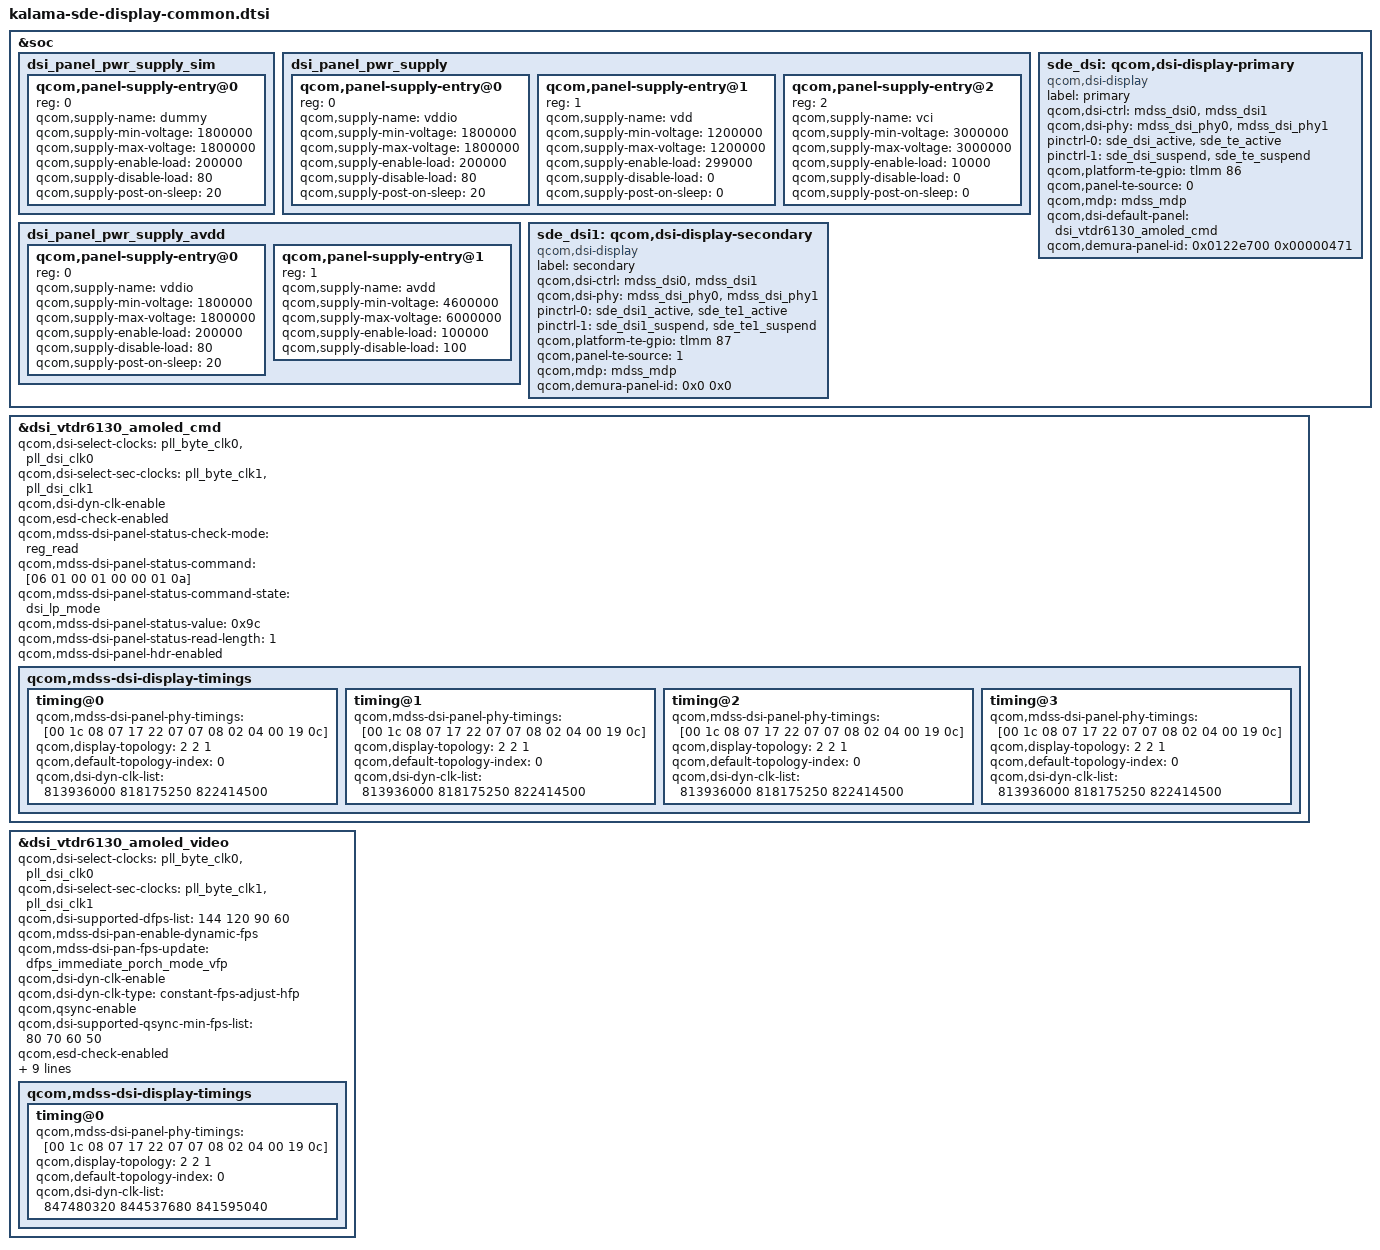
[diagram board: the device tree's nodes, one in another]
#include "dsi-panel-vtdr6130-dsc-fhd-plus-cmd.dtsi"
#include "dsi-panel-vtdr6130-dsc-fhd-plus-video.dtsi"

#include "kalama-sde-display-pinctrl.dtsi"

&soc {
	dsi_panel_pwr_supply_sim: dsi_panel_pwr_supply_sim {
		#address-cells = <1>;
		#size-cells = <0>;

		qcom,panel-supply-entry@0 {
			reg = <0>;
			qcom,supply-name = "dummy";
			qcom,supply-min-voltage = <1800000>;
			qcom,supply-max-voltage = <1800000>;
			qcom,supply-enable-load = <200000>;
			qcom,supply-disable-load = <80>;
			qcom,supply-post-on-sleep = <20>;
		};
	};

	dsi_panel_pwr_supply: dsi_panel_pwr_supply {
		#address-cells = <1>;
		#size-cells = <0>;

		qcom,panel-supply-entry@0 {
			reg = <0>;
			qcom,supply-name = "vddio";
			qcom,supply-min-voltage = <1800000>;
			qcom,supply-max-voltage = <1800000>;
			qcom,supply-enable-load = <200000>;
			qcom,supply-disable-load = <80>;
			qcom,supply-post-on-sleep = <20>;
		};

		qcom,panel-supply-entry@1 {
			reg = <1>;
			qcom,supply-name = "vdd";
			qcom,supply-min-voltage = <1200000>;
			qcom,supply-max-voltage = <1200000>;
			qcom,supply-enable-load = <299000>;
			qcom,supply-disable-load = <0>;
			qcom,supply-post-on-sleep = <0>;
		};

		qcom,panel-supply-entry@2 {
			reg = <2>;
			qcom,supply-name = "vci";
			qcom,supply-min-voltage = <3000000>;
			qcom,supply-max-voltage = <3000000>;
			qcom,supply-enable-load = <10000>;
			qcom,supply-disable-load = <0>;
			qcom,supply-post-on-sleep = <0>;
		};
	};

	dsi_panel_pwr_supply_avdd: dsi_panel_pwr_supply_avdd {
		#address-cells = <1>;
		#size-cells = <0>;

		qcom,panel-supply-entry@0 {
			reg = <0>;
			qcom,supply-name = "vddio";
			qcom,supply-min-voltage = <1800000>;
			qcom,supply-max-voltage = <1800000>;
			qcom,supply-enable-load = <200000>;
			qcom,supply-disable-load = <80>;
			qcom,supply-post-on-sleep = <20>;
		};

		qcom,panel-supply-entry@1 {
			reg = <1>;
			qcom,supply-name = "avdd";
			qcom,supply-min-voltage = <4600000>;
			qcom,supply-max-voltage = <6000000>;
			qcom,supply-enable-load = <100000>;
			qcom,supply-disable-load = <100>;
		};
	};

	sde_dsi: qcom,dsi-display-primary {
		compatible = "qcom,dsi-display";
		label = "primary";

		qcom,dsi-ctrl = <&mdss_dsi0 &mdss_dsi1>;
		qcom,dsi-phy = <&mdss_dsi_phy0 &mdss_dsi_phy1>;

		pinctrl-names = "panel_active", "panel_suspend";
		pinctrl-0 = <&sde_dsi_active &sde_te_active>;
		pinctrl-1 = <&sde_dsi_suspend &sde_te_suspend>;

		qcom,platform-te-gpio = <&tlmm 86 0>;
		qcom,panel-te-source = <0>;

		qcom,mdp = <&mdss_mdp>;
		qcom,dsi-default-panel = <&dsi_vtdr6130_amoled_cmd>;
		qcom,demura-panel-id = <0x0122e700 0x00000471>;
	};

	sde_dsi1: qcom,dsi-display-secondary {
		compatible = "qcom,dsi-display";
		label = "secondary";

		qcom,dsi-ctrl = <&mdss_dsi0 &mdss_dsi1>;
		qcom,dsi-phy = <&mdss_dsi_phy0 &mdss_dsi_phy1>;

		pinctrl-names = "panel_active", "panel_suspend";
		pinctrl-0 = <&sde_dsi1_active &sde_te1_active>;
		pinctrl-1 = <&sde_dsi1_suspend &sde_te1_suspend>;

		qcom,platform-te-gpio = <&tlmm 87 0>;
		qcom,panel-te-source = <1>;

		qcom,mdp = <&mdss_mdp>;
		qcom,demura-panel-id = <0x0 0x0>;
	};
};

/* PHY TIMINGS REVISION YL with reduced margins */
&dsi_vtdr6130_amoled_cmd {
	qcom,dsi-select-clocks = "pll_byte_clk0", "pll_dsi_clk0";
	qcom,dsi-select-sec-clocks = "pll_byte_clk1", "pll_dsi_clk1";

	qcom,dsi-dyn-clk-enable;

	qcom,esd-check-enabled;
	qcom,mdss-dsi-panel-status-check-mode = "reg_read";
	qcom,mdss-dsi-panel-status-command = [06 01 00 01 00 00 01 0a];
	qcom,mdss-dsi-panel-status-command-state = "dsi_lp_mode";
	qcom,mdss-dsi-panel-status-value = <0x9c>;
	qcom,mdss-dsi-panel-status-read-length = <1>;

	qcom,mdss-dsi-panel-hdr-enabled;

	qcom,mdss-dsi-display-timings {
		timing@0 {
			qcom,mdss-dsi-panel-phy-timings = [00 1c 08 07 17 22 07
				07 08 02 04 00 19 0c];
			qcom,display-topology = <2 2 1>;
			qcom,default-topology-index = <0>;
			qcom,dsi-dyn-clk-list = <813936000 818175250 822414500>;
		};
		timing@1 {
			qcom,mdss-dsi-panel-phy-timings = [00 1c 08 07 17 22 07
				07 08 02 04 00 19 0c];
			qcom,display-topology = <2 2 1>;
			qcom,default-topology-index = <0>;
			qcom,dsi-dyn-clk-list = <813936000 818175250 822414500>;
		};
		timing@2 {
			qcom,mdss-dsi-panel-phy-timings = [00 1c 08 07 17 22 07
				07 08 02 04 00 19 0c];
			qcom,display-topology = <2 2 1>;
			qcom,default-topology-index = <0>;
			qcom,dsi-dyn-clk-list = <813936000 818175250 822414500>;
		};
		timing@3 {
			qcom,mdss-dsi-panel-phy-timings = [00 1c 08 07 17 22 07
				07 08 02 04 00 19 0c];
			qcom,display-topology = <2 2 1>;
			qcom,default-topology-index = <0>;
			qcom,dsi-dyn-clk-list = <813936000 818175250 822414500>;
		};
	};
};

&dsi_vtdr6130_amoled_video {
	qcom,dsi-select-clocks = "pll_byte_clk0", "pll_dsi_clk0";
	qcom,dsi-select-sec-clocks = "pll_byte_clk1", "pll_dsi_clk1";
	qcom,dsi-supported-dfps-list = <144 120 90 60>;
	qcom,mdss-dsi-pan-enable-dynamic-fps;
	qcom,mdss-dsi-pan-fps-update = "dfps_immediate_porch_mode_vfp";

	qcom,dsi-dyn-clk-enable;
	qcom,dsi-dyn-clk-type = "constant-fps-adjust-hfp";

	qcom,qsync-enable;
	qcom,dsi-supported-qsync-min-fps-list = <80 70 60 50>;

	qcom,esd-check-enabled;
	qcom,mdss-dsi-panel-status-check-mode = "reg_read";
	qcom,mdss-dsi-panel-status-command = [06 01 00 01 00 00 01 0a];
	qcom,mdss-dsi-panel-status-command-state = "dsi_lp_mode";
	qcom,mdss-dsi-panel-status-value = <0x9c>;
	qcom,mdss-dsi-panel-status-read-length = <1>;

	qcom,mdss-dsi-panel-hdr-enabled;

	qcom,mdss-dsi-display-timings {
		timing@0 {
			qcom,mdss-dsi-panel-phy-timings = [00 1c 08 07 17 22 07
				07 08 02 04 00 19 0c];
			qcom,display-topology = <2 2 1>;
			qcom,default-topology-index = <0>;
			qcom,dsi-dyn-clk-list = <847480320 844537680 841595040>;
		};
	};
};
